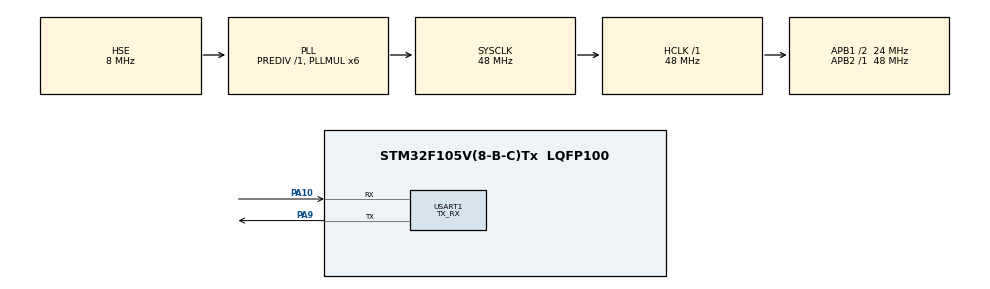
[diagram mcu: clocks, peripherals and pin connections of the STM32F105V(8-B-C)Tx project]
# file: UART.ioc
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Mcu.Family=STM32F1
Mcu.Name=STM32F105V(8-B-C)Tx
Mcu.Package=LQFP100
NVIC.PriorityGroup=NVIC_PRIORITYGROUP_4
NVIC.USART1_IRQn=true\:0\:0\:false\:false\:true\:true\:true
OSC_IN.Mode=HSE-External-Oscillator
OSC_IN.Signal=RCC_OSC_IN
OSC_OUT.Mode=HSE-External-Oscillator
OSC_OUT.Signal=RCC_OSC_OUT
PA10.Mode=Asynchronous
PA10.Signal=USART1_RX
PA13.Mode=Serial_Wire
PA13.Signal=SYS_JTMS-SWDIO
PA14.Mode=Serial_Wire
PA14.Signal=SYS_JTCK-SWCLK
PA9.Mode=Asynchronous
PA9.Signal=USART1_TX
ProjectManager.HeapSize=0x200
ProjectManager.StackSize=0x400
ProjectManager.TargetToolchain=MDK-ARM V5
RCC.AHBFreq_Value=48000000
RCC.APB1CLKDivider=RCC_HCLK_DIV2
RCC.APB1Freq_Value=24000000
RCC.APB1TimFreq_Value=48000000
RCC.APB2Freq_Value=48000000
RCC.APB2TimFreq_Value=48000000
RCC.HCLKFreq_Value=48000000
RCC.PLLMUL=RCC_PLL_MUL6
RCC.PLLSourceVirtual=RCC_PLLSOURCE_HSE
RCC.SYSCLKFreq_VALUE=48000000
RCC.SYSCLKSource=RCC_SYSCLKSOURCE_PLLCLK
RCC.USBFreq_Value=32000000
USART1.Mode=MODE_TX_RX
USART1.VirtualMode=VM_ASYNC
USART1.WordLength=WORDLENGTH_8B
board=custom

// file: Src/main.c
/* USER CODE BEGIN Header */
/**
  ******************************************************************************
  * @file           : main.c
  * @brief          : Main program body
  ******************************************************************************
  * @attention
  *
  * <h2><center>&copy; Copyright (c) 2019 STMicroelectronics.
  * All rights reserved.</center></h2>
  *
  * This software component is licensed by ST under BSD 3-Clause license,
  * the "License"; You may not use this file except in compliance with the
  * License. You may obtain a copy of the License at:
  *                        opensource.org/licenses/BSD-3-Clause
  *
  ******************************************************************************
  */
/* USER CODE END Header */

#include "main.h"

/* USER CODE BEGIN Includes */
#include <stdio.h>
/* USER CODE END Includes */

UART_HandleTypeDef huart1;

void SystemClock_Config(void);
static void MX_GPIO_Init(void);
static void MX_USART1_UART_Init(void);

/* USER CODE BEGIN 0 */
int fputc(int ch, FILE *f)
{
  HAL_UART_Transmit(&huart1, (unsigned char *)&ch, 1, 1000);

  return 1;
}
/* USER CODE END 0 */

int main(void)
{

  /* MCU Configuration--------------------------------------------------------*/

  /* Reset of all peripherals, Initializes the Flash interface and the Systick. */
  HAL_Init();

  /* Configure the system clock */
  SystemClock_Config();

  /* Initialize all configured peripherals */
  MX_GPIO_Init();
  MX_USART1_UART_Init();
  /* USER CODE BEGIN 2 */
  printf("This is STM32CobeMX uart print demo !!!\r\n");
  /* USER CODE END 2 */

  /* Infinite loop */
  while (1)
  {

  }
}

void SystemClock_Config(void)
{
  RCC_OscInitTypeDef RCC_OscInitStruct = {0};
  RCC_ClkInitTypeDef RCC_ClkInitStruct = {0};

  /** Initializes the CPU, AHB and APB busses clocks
  */
  RCC_OscInitStruct.OscillatorType = RCC_OSCILLATORTYPE_HSE;
  RCC_OscInitStruct.HSEState = RCC_HSE_ON;
  RCC_OscInitStruct.HSEPredivValue = RCC_HSE_PREDIV_DIV1;
  RCC_OscInitStruct.HSIState = RCC_HSI_ON;
  RCC_OscInitStruct.Prediv1Source = RCC_PREDIV1_SOURCE_HSE;
  RCC_OscInitStruct.PLL.PLLState = RCC_PLL_ON;
  RCC_OscInitStruct.PLL.PLLSource = RCC_PLLSOURCE_HSE;
  RCC_OscInitStruct.PLL.PLLMUL = RCC_PLL_MUL6;
  RCC_OscInitStruct.PLL2.PLL2State = RCC_PLL_NONE;
  if (HAL_RCC_OscConfig(&RCC_OscInitStruct) != HAL_OK)
  {
    Error_Handler();
  }
  /** Initializes the CPU, AHB and APB busses clocks
  */
  RCC_ClkInitStruct.ClockType = RCC_CLOCKTYPE_HCLK|RCC_CLOCKTYPE_SYSCLK
                              |RCC_CLOCKTYPE_PCLK1|RCC_CLOCKTYPE_PCLK2;
  RCC_ClkInitStruct.SYSCLKSource = RCC_SYSCLKSOURCE_PLLCLK;
  RCC_ClkInitStruct.AHBCLKDivider = RCC_SYSCLK_DIV1;
  RCC_ClkInitStruct.APB1CLKDivider = RCC_HCLK_DIV2;
  RCC_ClkInitStruct.APB2CLKDivider = RCC_HCLK_DIV1;

  if (HAL_RCC_ClockConfig(&RCC_ClkInitStruct, FLASH_LATENCY_1) != HAL_OK)
  {
    Error_Handler();
  }
  /** Configure the Systick interrupt time
  */
  __HAL_RCC_PLLI2S_ENABLE();
}

static void MX_USART1_UART_Init(void)
{

  huart1.Instance = USART1;
  huart1.Init.BaudRate = 115200;
  huart1.Init.WordLength = UART_WORDLENGTH_8B;
  huart1.Init.StopBits = UART_STOPBITS_1;
  huart1.Init.Parity = UART_PARITY_NONE;
  huart1.Init.Mode = UART_MODE_TX_RX;
  huart1.Init.HwFlowCtl = UART_HWCONTROL_NONE;
  huart1.Init.OverSampling = UART_OVERSAMPLING_16;
  if (HAL_UART_Init(&huart1) != HAL_OK)
  {
    Error_Handler();
  }

}

static void MX_GPIO_Init(void)
{

  /* GPIO Ports Clock Enable */
  __HAL_RCC_GPIOA_CLK_ENABLE();

}

void Error_Handler(void)
{
}

/************************ (C) COPYRIGHT STMicroelectronics *****END OF FILE****/
